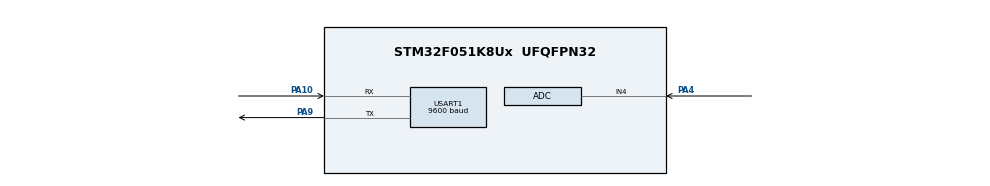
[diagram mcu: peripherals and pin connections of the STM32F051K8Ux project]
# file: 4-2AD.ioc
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ADC.SamplingTime=ADC_SAMPLETIME_239CYCLES_5
Mcu.Family=STM32F0
Mcu.Name=STM32F051K8Ux
Mcu.Package=UFQFPN32
NVIC.USART1_IRQn=true\:0\:0\:false\:false\:true\:true\:true\:true
PA10.Mode=Asynchronous
PA10.Signal=USART1_RX
PA4.Mode=IN4
PA4.Signal=ADC_IN4
PA9.Mode=Asynchronous
PA9.Signal=USART1_TX
ProjectManager.HeapSize=0x200
ProjectManager.StackSize=0x400
ProjectManager.TargetToolchain=MDK-ARM V5.32
USART1.BaudRate=9600
USART1.VirtualMode-Asynchronous=VM_ASYNC
board=custom

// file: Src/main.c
/* USER CODE BEGIN Header */
/**
  ******************************************************************************
  * @file           : main.c
  * @brief          : Main program body
  ******************************************************************************
  * @attention
  *
  * Copyright (c) 2023 STMicroelectronics.
  * All rights reserved.
  *
  * This software is licensed under terms that can be found in the LICENSE file
  * in the root directory of this software component.
  * If no LICENSE file comes with this software, it is provided AS-IS.
  *
  ******************************************************************************
  */
/* USER CODE END Header */
#include "main.h"
#include "adc.h"
#include "usart.h"
#include "gpio.h"

/* USER CODE BEGIN Includes */
#include <stdio.h>
/* USER CODE END Includes */

void SystemClock_Config(void);
/* USER CODE BEGIN PFP */
int fputc(int ch,FILE *fp){
  HAL_UART_Transmit(&huart1,(uint8_t *)&ch,1,HAL_MAX_DELAY);
  return ch;
}
/* USER CODE END PFP */

int main(void)
{

  /* MCU Configuration--------------------------------------------------------*/

  /* Reset of all peripherals, Initializes the Flash interface and the Systick. */
  HAL_Init();

  /* Configure the system clock */
  SystemClock_Config();

  /* Initialize all configured peripherals */
  MX_GPIO_Init();
  MX_ADC_Init();
  MX_USART1_UART_Init();

  /* Infinite loop */
  while (1)
  {

    /* USER CODE BEGIN 3 */
    HAL_ADC_Start(&hadc);

    HAL_ADC_PollForConversion(&hadc,HAL_MAX_DELAY);

    uint8_t reseult=HAL_ADC_GetValue(&hadc);

    printf("%d\n\r",reseult);

    //printf("%d\n",reseult);

    HAL_Delay(1000);
  }
  /* USER CODE END 3 */
}

void SystemClock_Config(void)
{
  RCC_OscInitTypeDef RCC_OscInitStruct = {0};
  RCC_ClkInitTypeDef RCC_ClkInitStruct = {0};
  RCC_PeriphCLKInitTypeDef PeriphClkInit = {0};

  /** Initializes the RCC Oscillators according to the specified parameters
  * in the RCC_OscInitTypeDef structure.
  */
  RCC_OscInitStruct.OscillatorType = RCC_OSCILLATORTYPE_HSI|RCC_OSCILLATORTYPE_HSI14;
  RCC_OscInitStruct.HSIState = RCC_HSI_ON;
  RCC_OscInitStruct.HSI14State = RCC_HSI14_ON;
  RCC_OscInitStruct.HSICalibrationValue = RCC_HSICALIBRATION_DEFAULT;
  RCC_OscInitStruct.HSI14CalibrationValue = 16;
  RCC_OscInitStruct.PLL.PLLState = RCC_PLL_NONE;
  if (HAL_RCC_OscConfig(&RCC_OscInitStruct) != HAL_OK)
  {
    Error_Handler();
  }

  /** Initializes the CPU, AHB and APB buses clocks
  */
  RCC_ClkInitStruct.ClockType = RCC_CLOCKTYPE_HCLK|RCC_CLOCKTYPE_SYSCLK
                              |RCC_CLOCKTYPE_PCLK1;
  RCC_ClkInitStruct.SYSCLKSource = RCC_SYSCLKSOURCE_HSI;
  RCC_ClkInitStruct.AHBCLKDivider = RCC_SYSCLK_DIV1;
  RCC_ClkInitStruct.APB1CLKDivider = RCC_HCLK_DIV1;

  if (HAL_RCC_ClockConfig(&RCC_ClkInitStruct, FLASH_LATENCY_0) != HAL_OK)
  {
    Error_Handler();
  }
  PeriphClkInit.PeriphClockSelection = RCC_PERIPHCLK_USART1;
  PeriphClkInit.Usart1ClockSelection = RCC_USART1CLKSOURCE_PCLK1;
  if (HAL_RCCEx_PeriphCLKConfig(&PeriphClkInit) != HAL_OK)
  {
    Error_Handler();
  }
}

void Error_Handler(void)
{
  __disable_irq();
  while (1)
  {
  }
}
